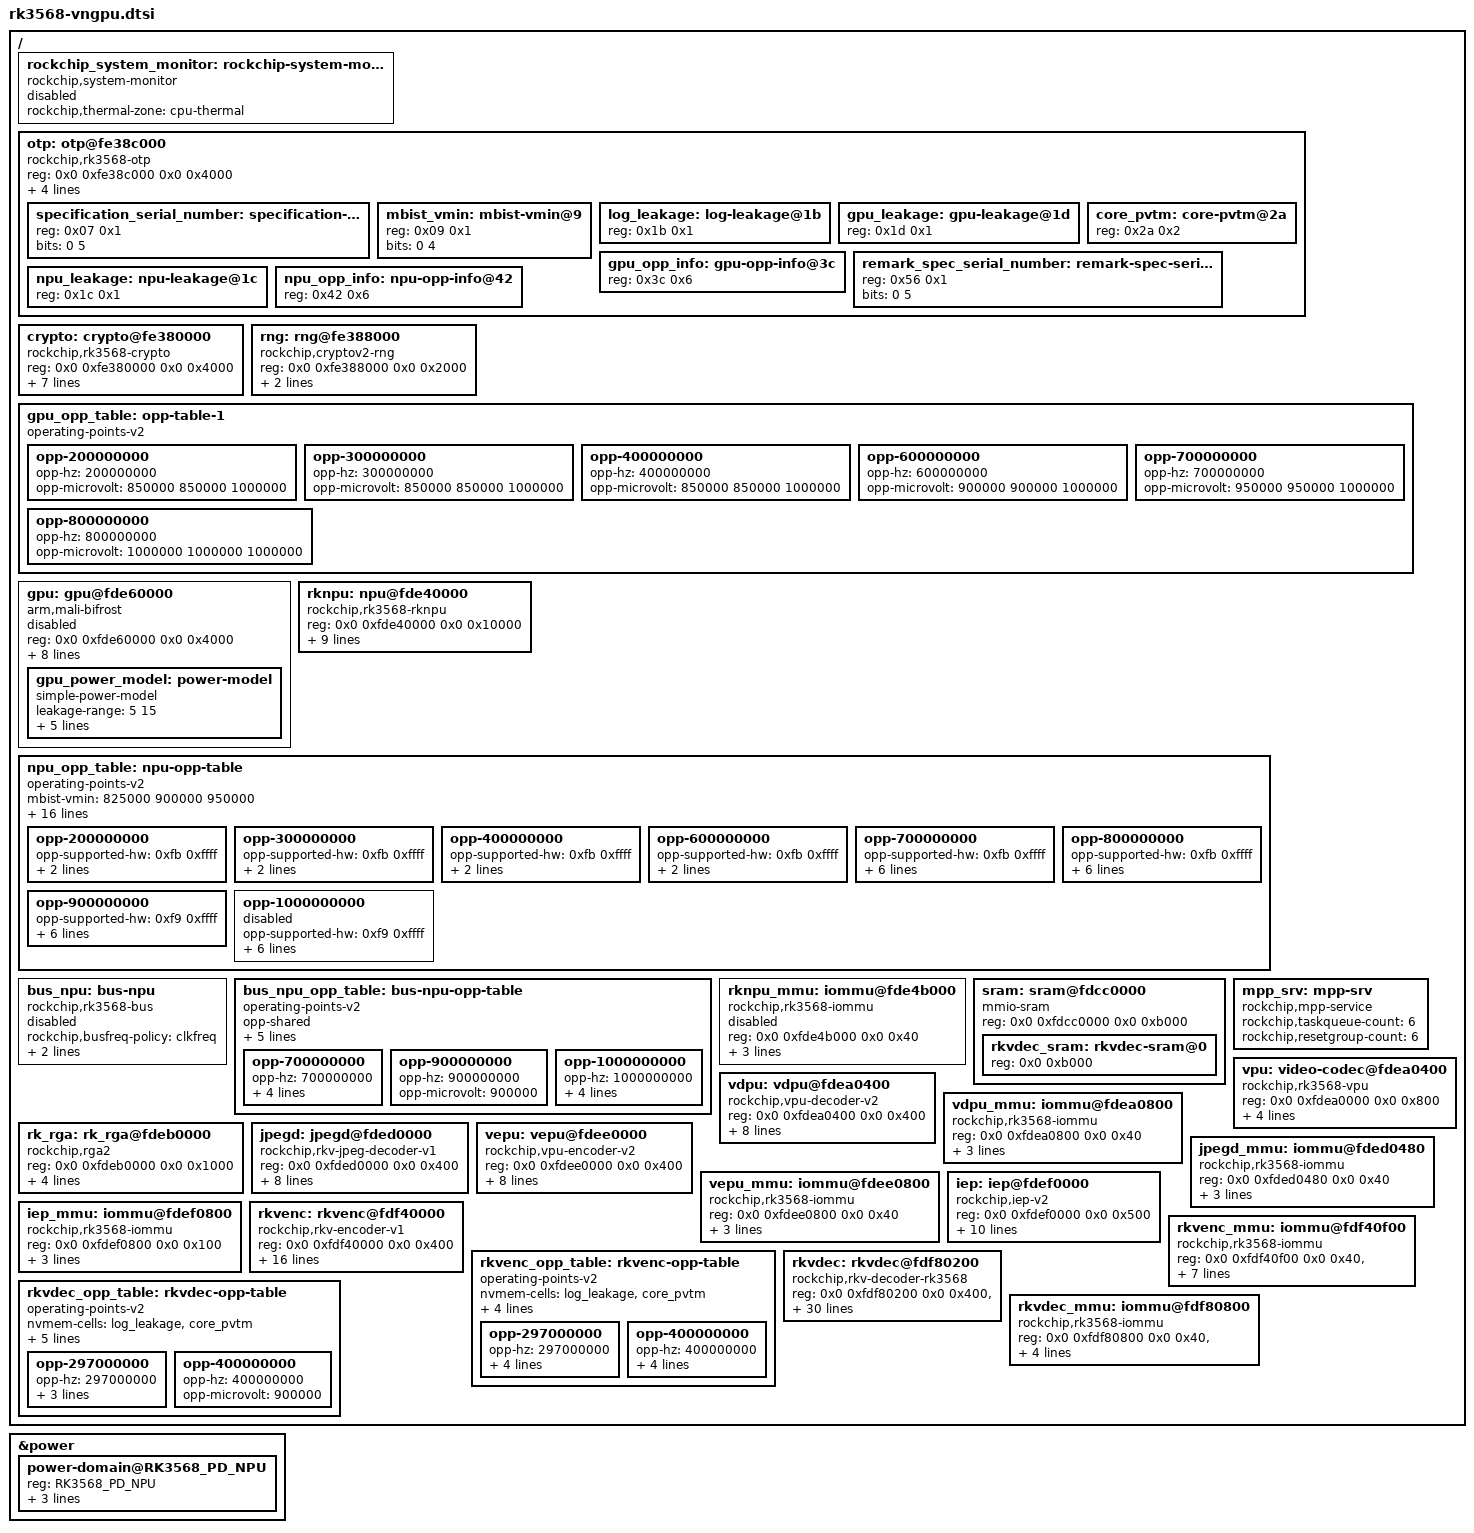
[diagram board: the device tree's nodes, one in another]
/*
 * Copyright (c) 2021 Rockchip Electronics Co., Ltd.
 */

/delete-node/ &vepu;

/ {

	rockchip_system_monitor: rockchip-system-monitor {
		compatible = "rockchip,system-monitor";

		rockchip,thermal-zone = "cpu-thermal";
		status = "disabled";
	};

	otp: otp@fe38c000 {
		compatible = "rockchip,rk3568-otp";
		reg = <0x0 0xfe38c000 0x0 0x4000>;
		#address-cells = <1>;
		#size-cells = <1>;
		clocks = <&cru CLK_OTPC_NS_USR>, <&cru CLK_OTPC_NS_SBPI>,
				<&cru PCLK_OTPC_NS>, <&cru PCLK_OTPPHY>;
		clock-names = "otp", "sbpi", "apb_pclk", "phy";
		resets = <&cru SRST_OTPPHY>;
		reset-names = "otp_phy";

		specification_serial_number: specification-serial-number@7 {
			reg = <0x07 0x1>;
			bits = <0 5>;
		};
		mbist_vmin: mbist-vmin@9 {
			reg = <0x09 0x1>;
			bits = <0 4>;
		};
		log_leakage: log-leakage@1b {
			reg = <0x1b 0x1>;
		};
		gpu_leakage: gpu-leakage@1d {
			reg = <0x1d 0x1>;
		};
		core_pvtm:core-pvtm@2a {
			reg = <0x2a 0x2>;
		};
		gpu_opp_info: gpu-opp-info@3c {
			reg = <0x3c 0x6>;
		};
		remark_spec_serial_number: remark-spec-serial-number@56 {
			reg = <0x56 0x1>;
			bits = <0 5>;
		};
	};

	crypto: crypto@fe380000 {
		compatible = "rockchip,rk3568-crypto";
		reg = <0x0 0xfe380000 0x0 0x4000>;
		interrupts = <GIC_SPI 4 IRQ_TYPE_LEVEL_HIGH>;
		clocks = <&cru ACLK_CRYPTO_NS>, <&cru HCLK_CRYPTO_NS>,
			<&cru CLK_CRYPTO_NS_CORE>, <&cru CLK_CRYPTO_NS_PKA>;
		clock-names = "aclk", "hclk", "sclk", "apb_pclk";
		assigned-clocks = <&cru CLK_CRYPTO_NS_CORE>;
		assigned-clock-rates = <200000000>;
		resets = <&cru SRST_CRYPTO_NS_CORE>;
		reset-names = "crypto-rst";
		status = "disabled";
	};

	rng: rng@fe388000 {
		compatible = "rockchip,cryptov2-rng", "rockchip,rk3568-rng";
		reg = <0x0 0xfe388000 0x0 0x2000>;
		clocks = <&cru CLK_TRNG_NS>, <&cru HCLK_TRNG_NS>;
		clock-names = "clk_trng", "hclk_trng";
		resets = <&cru SRST_TRNG_NS>;
		reset-names = "reset";
		status = "disabled";
	};
	
	gpu_opp_table: opp-table-1 {
		compatible = "operating-points-v2";

		opp-200000000 {
			opp-hz = /bits/ 64 <200000000>;
			opp-microvolt = <850000 850000 1000000>;
		};

		opp-300000000 {
			opp-hz = /bits/ 64 <300000000>;
			opp-microvolt = <850000 850000 1000000>;
		};

		opp-400000000 {
			opp-hz = /bits/ 64 <400000000>;
			opp-microvolt = <850000 850000 1000000>;
		};

		opp-600000000 {
			opp-hz = /bits/ 64 <600000000>;
			opp-microvolt = <900000 900000 1000000>;
		};

		opp-700000000 {
			opp-hz = /bits/ 64 <700000000>;
			opp-microvolt = <950000 950000 1000000>;
		};

		opp-800000000 {
			opp-hz = /bits/ 64 <800000000>;
			opp-microvolt = <1000000 1000000 1000000>;
		};
	};

	gpu: gpu@fde60000 {
		compatible = "arm,mali-bifrost";
		reg = <0x0 0xfde60000 0x0 0x4000>;

		interrupts = <GIC_SPI 39 IRQ_TYPE_LEVEL_HIGH>,
			     <GIC_SPI 41 IRQ_TYPE_LEVEL_HIGH>,
			     <GIC_SPI 40 IRQ_TYPE_LEVEL_HIGH>;
		interrupt-names = "gpu", "mmu", "job";

		upthreshold = <40>;
		downdifferential = <10>;

		clocks = <&scmi_clk 1>, <&cru CLK_GPU>;
		clock-names = "gpu", "bus";
		power-domains = <&power RK3568_PD_GPU>;
		#cooling-cells = <2>;
		operating-points-v2 = <&gpu_opp_table>;

		status = "disabled";
		gpu_power_model: power-model {
			compatible = "simple-power-model";
			leakage-range= <5 15>;
			ls = <(-24002) 22823 0>;
			static-coefficient = <100000>;
			dynamic-coefficient = <953>;
			ts = <(-108890) 63610 (-1355) 20>;
			thermal-zone = "gpu-thermal";
		};
	};

	rknpu: npu@fde40000 {
		compatible = "rockchip,rk3568-rknpu", "rockchip,rknpu";
		reg = <0x0 0xfde40000 0x0 0x10000>;
		interrupts = <GIC_SPI 151 IRQ_TYPE_LEVEL_HIGH>;
		interrupt-names = "npu_irq";
		clocks = <&scmi_clk 2>, <&cru CLK_NPU>, <&cru ACLK_NPU>, <&cru HCLK_NPU>;
		clock-names = "scmi_clk", "clk", "aclk", "hclk";
		assigned-clocks = <&cru CLK_NPU>;
		assigned-clock-rates = <600000000>;
		resets = <&cru SRST_A_NPU>, <&cru SRST_H_NPU>;
		reset-names = "srst_a", "srst_h";
		power-domains = <&power RK3568_PD_NPU>;
		operating-points-v2 = <&npu_opp_table>;
		iommus = <&rknpu_mmu>;
		status = "disabled";
	};

	npu_opp_table: npu-opp-table {
		compatible = "operating-points-v2";

		mbist-vmin = <825000 900000 950000>;
		nvmem-cells = <&npu_leakage>, <&core_pvtm>, <&mbist_vmin>, <&npu_opp_info>,
			      <&specification_serial_number>, <&remark_spec_serial_number>;
		nvmem-cell-names = "leakage", "pvtm", "mbist-vmin", "opp-info",
				   "specification_serial_number", "remark_spec_serial_number";
		rockchip,supported-hw;
		rockchip,max-volt = <1000000>;
		rockchip,temp-hysteresis = <5000>;
		rockchip,low-temp = <0>;
		rockchip,low-temp-adjust-volt = <
			/* MHz    MHz    uV */
			   0      1000    50000
		>;
		rockchip,pvtm-voltage-sel = <
			0        84000   0
			84001    87000   1
			87001    91000   2
			91001    100000  3
		>;
		rockchip,pvtm-ch = <0 5>;
		rockchip,init-freq = <900000>;

		/* RK3568 && RK3568M npu OPPs */
		opp-200000000 {
			opp-supported-hw = <0xfb 0xffff>;
			opp-hz = /bits/ 64 <200000000>;
			opp-microvolt = <850000 850000 1000000>;
		};
		opp-300000000 {
			opp-supported-hw = <0xfb 0xffff>;
			opp-hz = /bits/ 64 <297000000>;
			opp-microvolt = <850000 850000 1000000>;
		};
		opp-400000000 {
			opp-supported-hw = <0xfb 0xffff>;
			opp-hz = /bits/ 64 <400000000>;
			opp-microvolt = <850000 850000 1000000>;
		};
		opp-600000000 {
			opp-supported-hw = <0xfb 0xffff>;
			opp-hz = /bits/ 64 <600000000>;
			opp-microvolt = <850000 850000 1000000>;
		};
		opp-700000000 {
			opp-supported-hw = <0xfb 0xffff>;
			opp-hz = /bits/ 64 <700000000>;
			opp-microvolt = <875000 875000 1000000>;
			opp-microvolt-L0 = <875000 875000 1000000>;
			opp-microvolt-L1 = <850000 850000 1000000>;
			opp-microvolt-L2 = <850000 850000 1000000>;
			opp-microvolt-L3 = <850000 850000 1000000>;
		};
		opp-800000000 {
			opp-supported-hw = <0xfb 0xffff>;
			opp-hz = /bits/ 64 <800000000>;
			opp-microvolt = <925000 925000 1000000>;
			opp-microvolt-L0 = <925000 925000 1000000>;
			opp-microvolt-L1 = <900000 900000 1000000>;
			opp-microvolt-L2 = <875000 875000 1000000>;
			opp-microvolt-L3 = <875000 875000 1000000>;
		};
		opp-900000000 {
			opp-supported-hw = <0xf9 0xffff>;
			opp-hz = /bits/ 64 <900000000>;
			opp-microvolt = <975000 975000 1000000>;
			opp-microvolt-L0 = <975000 975000 1000000>;
			opp-microvolt-L1 = <950000 950000 1000000>;
			opp-microvolt-L2 = <925000 925000 1000000>;
			opp-microvolt-L3 = <900000 900000 1000000>;
		};
		opp-1000000000 {
			opp-supported-hw = <0xf9 0xffff>;
			opp-hz = /bits/ 64 <1000000000>;
			opp-microvolt = <1000000 1000000 1000000>;
			opp-microvolt-L0 = <1000000 1000000 1000000>;
			opp-microvolt-L1 = <975000 975000 1000000>;
			opp-microvolt-L2 = <950000 950000 1000000>;
			opp-microvolt-L3 = <925000 925000 1000000>;
			status = "disabled";
		};
	};

	bus_npu: bus-npu {
		compatible = "rockchip,rk3568-bus";
		rockchip,busfreq-policy = "clkfreq";
		clocks = <&scmi_clk 2>;
		clock-names = "bus";
		operating-points-v2 = <&bus_npu_opp_table>;
		status = "disabled";
	};

	bus_npu_opp_table: bus-npu-opp-table {
		compatible = "operating-points-v2";
		opp-shared;

		nvmem-cells = <&core_pvtm>;
		nvmem-cell-names = "pvtm";
		rockchip,pvtm-voltage-sel = <
			0        84000   0
			84001    91000   1
			91001    100000  2
		>;
		rockchip,pvtm-ch = <0 5>;

		opp-700000000 {
			opp-hz = /bits/ 64 <700000000>;
			opp-microvolt = <900000>;
			opp-microvolt-L0 = <900000>;
			opp-microvolt-L1 = <875000>;
			opp-microvolt-L2 = <875000>;
		};
		opp-900000000 {
			opp-hz = /bits/ 64 <900000000>;
			opp-microvolt = <900000>;
		};
		opp-1000000000 {
			opp-hz = /bits/ 64 <1000000000>;
			opp-microvolt = <950000>;
			opp-microvolt-L0 = <950000>;
			opp-microvolt-L1 = <925000>;
			opp-microvolt-L2 = <900000>;
		};
	};

	rknpu_mmu: iommu@fde4b000 {
		compatible = "rockchip,rk3568-iommu", "rockchip,iommu-v2";
		reg = <0x0 0xfde4b000 0x0 0x40>;
		interrupts = <GIC_SPI 151 IRQ_TYPE_LEVEL_HIGH>;
		interrupt-names = "rknpu_mmu";
		clocks = <&cru ACLK_NPU>, <&cru HCLK_NPU>;
		clock-names = "aclk", "iface";
		power-domains = <&power RK3568_PD_NPU>;
		#iommu-cells = <0>;
		status = "disabled";
	};

	sram: sram@fdcc0000 {
		compatible = "mmio-sram";
		reg = <0x0 0xfdcc0000 0x0 0xb000>;

		#address-cells = <1>;
		#size-cells = <1>;
		ranges = <0x0 0x0 0xfdcc0000 0xb000>;

		/* start address and size should be 4k algin */
		rkvdec_sram: rkvdec-sram@0 {
			reg = <0x0 0xb000>;
		};
	};

	mpp_srv: mpp-srv {
		compatible = "rockchip,mpp-service";
		rockchip,taskqueue-count = <6>;
		rockchip,resetgroup-count = <6>;
		status = "disabled";
	};

	vpu: video-codec@fdea0400 {
		compatible = "rockchip,rk3568-vpu";
		reg = <0x0 0xfdea0000 0x0 0x800>;
		interrupts = <GIC_SPI 139 IRQ_TYPE_LEVEL_HIGH>;
		clocks = <&cru ACLK_VPU>, <&cru HCLK_VPU>;
		clock-names = "aclk", "hclk";
		iommus = <&vdpu_mmu>;
		power-domains = <&power RK3568_PD_VPU>;
	};

	vdpu: vdpu@fdea0400 {
		compatible = "rockchip,vpu-decoder-v2";
		reg = <0x0 0xfdea0400 0x0 0x400>;
		interrupts = <GIC_SPI 139 IRQ_TYPE_LEVEL_HIGH>;
		interrupt-names = "irq_dec";
		clocks = <&cru ACLK_VPU>, <&cru HCLK_VPU>;
		clock-names = "aclk_vcodec", "hclk_vcodec";
		resets = <&cru SRST_A_VPU>, <&cru SRST_H_VPU>;
		reset-names = "video_a", "video_h";
		iommus = <&vdpu_mmu>;
		power-domains = <&power RK3568_PD_VPU>;
		rockchip,srv = <&mpp_srv>;
		rockchip,taskqueue-node = <0>;
		rockchip,resetgroup-node = <0>;
		status = "disabled";
	};

	vdpu_mmu: iommu@fdea0800 {
		compatible = "rockchip,rk3568-iommu", "rockchip,iommu-v2";
		reg = <0x0 0xfdea0800 0x0 0x40>;
		interrupts = <GIC_SPI 138 IRQ_TYPE_LEVEL_HIGH>;
		interrupt-names = "vdpu_mmu";
		clock-names = "aclk", "iface";
		clocks = <&cru ACLK_VPU>, <&cru HCLK_VPU>;
		power-domains = <&power RK3568_PD_VPU>;
		#iommu-cells = <0>;
		status = "disabled";
	};

	rk_rga: rk_rga@fdeb0000 {
		compatible = "rockchip,rga2";
		reg = <0x0 0xfdeb0000 0x0 0x1000>;
		interrupts = <GIC_SPI 90 IRQ_TYPE_LEVEL_HIGH>;
		clocks = <&cru ACLK_RGA>, <&cru HCLK_RGA>, <&cru CLK_RGA_CORE>;
		clock-names = "aclk_rga", "hclk_rga", "clk_rga";
		power-domains = <&power RK3568_PD_RGA>;
		status = "disabled";
	};

	jpegd: jpegd@fded0000 {
		compatible = "rockchip,rkv-jpeg-decoder-v1";
		reg = <0x0 0xfded0000 0x0 0x400>;
		interrupts = <GIC_SPI 62 IRQ_TYPE_LEVEL_HIGH>;
		clocks = <&cru ACLK_JDEC>, <&cru HCLK_JDEC>;
		clock-names = "aclk_vcodec", "hclk_vcodec";
		resets = <&cru SRST_A_JDEC>, <&cru SRST_H_JDEC>;
		reset-names = "video_a", "video_h";
		iommus = <&jpegd_mmu>;
		rockchip,srv = <&mpp_srv>;
		rockchip,taskqueue-node = <1>;
		rockchip,resetgroup-node = <1>;
		power-domains = <&power RK3568_PD_RGA>;
		status = "disabled";
	};

	jpegd_mmu: iommu@fded0480 {
		compatible = "rockchip,rk3568-iommu", "rockchip,iommu-v2";
		reg = <0x0 0xfded0480 0x0 0x40>;
		interrupts = <GIC_SPI 61 IRQ_TYPE_LEVEL_HIGH>;
		interrupt-names = "jpegd_mmu";
		clock-names = "aclk", "iface";
		clocks = <&cru ACLK_JDEC>, <&cru HCLK_JDEC>;
		power-domains = <&power RK3568_PD_RGA>;
		#iommu-cells = <0>;
		status = "disabled";
	};

	vepu: vepu@fdee0000 {
		compatible = "rockchip,vpu-encoder-v2";
		reg = <0x0 0xfdee0000 0x0 0x400>;
		interrupts = <GIC_SPI 64 IRQ_TYPE_LEVEL_HIGH>;
		clocks = <&cru ACLK_JENC>, <&cru HCLK_JENC>;
		clock-names = "aclk_vcodec", "hclk_vcodec";
		resets = <&cru SRST_A_JENC>, <&cru SRST_H_JENC>;
		reset-names = "video_a", "video_h";
		iommus = <&vepu_mmu>;
		rockchip,srv = <&mpp_srv>;
		rockchip,taskqueue-node = <2>;
		rockchip,resetgroup-node = <2>;
		power-domains = <&power RK3568_PD_RGA>;
		status = "disabled";
	};

	vepu_mmu: iommu@fdee0800 {
		compatible = "rockchip,rk3568-iommu", "rockchip,iommu-v2";
		reg = <0x0 0xfdee0800 0x0 0x40>;
		interrupts = <GIC_SPI 63 IRQ_TYPE_LEVEL_HIGH>;
		interrupt-names = "vepu_mmu";
		clocks = <&cru ACLK_JENC>, <&cru HCLK_JENC>;
		clock-names = "aclk", "iface";
		power-domains = <&power RK3568_PD_RGA>;
		#iommu-cells = <0>;
		status = "disabled";
	};

	iep: iep@fdef0000 {
		compatible = "rockchip,iep-v2";
		reg = <0x0 0xfdef0000 0x0 0x500>;
		interrupts = <GIC_SPI 56 IRQ_TYPE_LEVEL_HIGH>;
		clocks = <&cru ACLK_IEP>, <&cru HCLK_IEP>, <&cru CLK_IEP_CORE>;
		clock-names = "aclk", "hclk", "sclk";
		resets = <&cru SRST_A_IEP>, <&cru SRST_H_IEP>,
			<&cru SRST_IEP_CORE>;
		reset-names = "rst_a", "rst_h", "rst_s";
		power-domains = <&power RK3568_PD_RGA>;
		rockchip,srv = <&mpp_srv>;
		rockchip,taskqueue-node = <5>;
		rockchip,resetgroup-node = <5>;
		iommus = <&iep_mmu>;
		status = "disabled";
	};

	iep_mmu: iommu@fdef0800 {
		compatible = "rockchip,rk3568-iommu", "rockchip,iommu-v2";
		reg = <0x0 0xfdef0800 0x0 0x100>;
		interrupts = <GIC_SPI 56 IRQ_TYPE_LEVEL_HIGH>;
		interrupt-names = "iep_mmu";
		clocks = <&cru ACLK_IEP>, <&cru HCLK_IEP>;
		clock-names = "aclk", "iface";
		#iommu-cells = <0>;
		power-domains = <&power RK3568_PD_RGA>;
		//rockchip,disable-device-link-resume;
		status = "disabled";
	};

	rkvenc: rkvenc@fdf40000 {
		compatible = "rockchip,rkv-encoder-v1";
		reg = <0x0 0xfdf40000 0x0 0x400>;
		interrupts = <GIC_SPI 140 IRQ_TYPE_LEVEL_HIGH>;
		interrupt-names = "irq_enc";
		clocks = <&cru ACLK_RKVENC>, <&cru HCLK_RKVENC>,
			<&cru CLK_RKVENC_CORE>;
		clock-names = "aclk_vcodec", "hclk_vcodec", "clk_core";
		rockchip,normal-rates = <297000000>, <0>, <297000000>;
		resets = <&cru SRST_A_RKVENC>, <&cru SRST_H_RKVENC>,
			<&cru SRST_RKVENC_CORE>;
		reset-names = "video_a", "video_h", "video_core";
		assigned-clocks = <&cru ACLK_RKVENC>, <&cru CLK_RKVENC_CORE>;
		assigned-clock-rates = <297000000>, <297000000>;
		iommus = <&rkvenc_mmu>;
		node-name = "rkvenc";
		rockchip,srv = <&mpp_srv>;
		rockchip,taskqueue-node = <3>;
		rockchip,resetgroup-node = <3>;
		power-domains = <&power RK3568_PD_RKVENC>;
		operating-points-v2 = <&rkvenc_opp_table>;
		status = "disabled";
	};

	rkvenc_opp_table: rkvenc-opp-table {
		compatible = "operating-points-v2";

		nvmem-cells = <&log_leakage>, <&core_pvtm>;
		nvmem-cell-names = "leakage", "pvtm";
		rockchip,pvtm-voltage-sel = <
			0        84000   0
			84001    91000   1
			91001    100000  2
		>;
		rockchip,pvtm-ch = <0 5>;

		opp-297000000 {
			opp-hz = /bits/ 64 <297000000>;
			opp-microvolt = <900000>;
			opp-microvolt-L0 = <900000>;
			opp-microvolt-L1 = <875000>;
			opp-microvolt-L2 = <875000>;
		};
		opp-400000000 {
			opp-hz = /bits/ 64 <400000000>;
			opp-microvolt = <950000>;
			opp-microvolt-L0 = <950000>;
			opp-microvolt-L1 = <925000>;
			opp-microvolt-L2 = <900000>;
		};
	};

	rkvenc_mmu: iommu@fdf40f00 {
		compatible = "rockchip,rk3568-iommu", "rockchip,iommu-v2";
		reg = <0x0 0xfdf40f00 0x0 0x40>, <0x0 0xfdf40f40 0x0 0x40>;
		interrupts = <GIC_SPI 141 IRQ_TYPE_LEVEL_HIGH>,
			<GIC_SPI 142 IRQ_TYPE_LEVEL_HIGH>;
		interrupt-names = "rkvenc_mmu0", "rkvenc_mmu1";
		clocks = <&cru ACLK_RKVENC>, <&cru HCLK_RKVENC>;
		clock-names = "aclk", "iface";
		rockchip,disable-mmu-reset;
		rockchip,enable-cmd-retry;
		#iommu-cells = <0>;
		power-domains = <&power RK3568_PD_RKVENC>;
		status = "disabled";
	};

	rkvdec: rkvdec@fdf80200 {
		compatible = "rockchip,rkv-decoder-rk3568", "rockchip,rkv-decoder-v2";
		reg = <0x0 0xfdf80200 0x0 0x400>, <0x0 0xfdf80100 0x0 0x100>;
		reg-names = "regs", "link";
		interrupts = <GIC_SPI 91 IRQ_TYPE_LEVEL_HIGH>;
		interrupt-names = "irq_dec";
		clocks = <&cru ACLK_RKVDEC>, <&cru HCLK_RKVDEC>,
			 <&cru CLK_RKVDEC_CA>, <&cru CLK_RKVDEC_CORE>,
			 <&cru CLK_RKVDEC_HEVC_CA>;
		clock-names = "aclk_vcodec", "hclk_vcodec","clk_cabac",
			      "clk_core", "clk_hevc_cabac";
		rockchip,normal-rates = <297000000>, <0>, <297000000>,
					<297000000>, <600000000>;
		rockchip,advanced-rates = <396000000>, <0>, <396000000>,
					<396000000>, <600000000>;
		rockchip,default-max-load = <2088960>;
		resets = <&cru SRST_A_RKVDEC>, <&cru SRST_H_RKVDEC>, <&cru SRST_RKVDEC_CA>,
		<&cru SRST_RKVDEC_CORE>, <&cru SRST_RKVDEC_HEVC_CA>,
		<&cru SRST_A_RKVDEC_NIU>, <&cru SRST_H_RKVDEC_NIU>;
		assigned-clocks = <&cru ACLK_RKVDEC>, <&cru CLK_RKVDEC_CA>, <&cru CLK_RKVDEC_CORE>, <&cru CLK_RKVDEC_HEVC_CA>;
		assigned-clock-rates = <297000000>, <297000000>, <297000000>, <297000000>;
		reset-names = "video_a", "video_h", "video_cabac", "video_core", "video_hevc_cabac",
		"shared_niu_a", "shared_niu_h";
		power-domains = <&power RK3568_PD_RKVDEC>;
		operating-points-v2 = <&rkvdec_opp_table>;
		vdec-supply = <&vdd_logic>;
		iommus = <&rkvdec_mmu>;
		rockchip,srv = <&mpp_srv>;
		rockchip,taskqueue-node = <4>;
		rockchip,resetgroup-node = <4>;
		rockchip,sram = <&rkvdec_sram>;
		/* rcb_iova: start and size */
		rockchip,rcb-iova = <0x10000000 65536>;
		rockchip,rcb-min-width = <512>;
		rockchip,task-capacity = <16>;
		status = "disabled";
	};

	rkvdec_opp_table: rkvdec-opp-table {
		compatible = "operating-points-v2";

		nvmem-cells = <&log_leakage>, <&core_pvtm>;
		nvmem-cell-names = "leakage", "pvtm";
		rockchip,leakage-voltage-sel = <
			1   80    0
			81  254   1
		>;
		rockchip,pvtm-voltage-sel = <
			0        84000   0
			84001    100000  1
		>;
		rockchip,pvtm-ch = <0 5>;

		opp-297000000 {
			opp-hz = /bits/ 64 <297000000>;
			opp-microvolt = <900000>;
			opp-microvolt-L0 = <900000>;
			opp-microvolt-L1 = <875000>;
		};
		opp-400000000 {
			opp-hz = /bits/ 64 <400000000>;
			opp-microvolt = <900000>;
		};
	};

	rkvdec_mmu: iommu@fdf80800 {
		compatible = "rockchip,rk3568-iommu", "rockchip,iommu-v2";
		reg = <0x0 0xfdf80800 0x0 0x40>, <0x0 0xfdf80840 0x0 0x40>;
		interrupts = <GIC_SPI 92 IRQ_TYPE_LEVEL_HIGH>;
		interrupt-names = "rkvdec_mmu";
		clocks = <&cru ACLK_RKVDEC>, <&cru HCLK_RKVDEC>;
		clock-names = "aclk", "iface";
		power-domains = <&power RK3568_PD_RKVDEC>;
		#iommu-cells = <0>;
		status = "disabled";
	};
};

&crypto {
	status = "okay";
};

&rng {
	status = "okay";
};

&otp {
	gpu_leakage: gpu-leakage@1d {
		reg = <0x1d 0x1>;
	};
	gpu_opp_info: gpu-opp-info@3c {
		reg = <0x3c 0x6>;
	};
	npu_leakage: npu-leakage@1c {
		reg = <0x1c 0x1>;
	};
	npu_opp_info: npu-opp-info@42 {
		reg = <0x42 0x6>;
	};
};

&power {
	// vcc-supply = <&vdd_npu>;
	// These power domains are grouped by VD_NPU
	power-domain@RK3568_PD_NPU {
		reg = <RK3568_PD_NPU>;
		clocks = <&cru ACLK_NPU_PRE>,
				<&cru HCLK_NPU_PRE>,
				<&cru PCLK_NPU_PRE>;
		pm_qos = <&qos_npu>;
		#power-domain-cells = <0>;
	};
};

&iep {
	status = "okay";
};

&iep_mmu {
	status = "okay";
};

&jpegd {
	status = "okay";
};

&jpegd_mmu {
	status = "okay";
};

&mpp_srv {
	status = "okay";
};

&rk_rga {
	status = "okay";
};

&rkvdec {
	status = "okay";
};

&rkvdec_mmu {
	status = "okay";
};

&rkvenc {
	status = "okay";
};

&rkvenc_mmu {
	status = "okay";
};

&vdpu {
	status = "okay";
};

&vdpu_mmu {
	status = "okay";
};

&vepu {
	status = "okay";
};

&vepu_mmu {
	status = "okay";
};

&rknpu {
	status = "okay";
};
